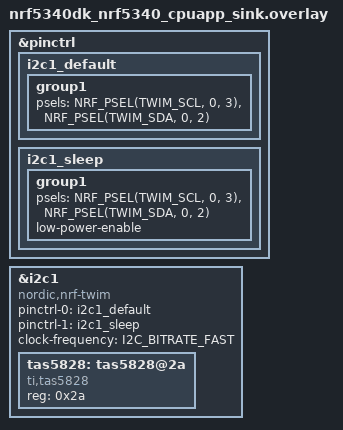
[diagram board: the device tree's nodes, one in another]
/*
 * boards/nrf5340dk_nrf5340_cpuapp_sink.overlay
 *
 * DTS overlay específico para builds de broadcast_sink (BT40NE).
 * Habilita I2C1 y declara el amplificador TAS5828.
 *
 * Pines I2C confirmados para TAS5828:
 *   SCL → P0.03
 *   SDA → P0.02
 *   I2C address TAS5828 → 0x2A  (ADDR pin = GND)
 *
 * Copyright (c) 2026
 * SPDX-License-Identifier: LicenseRef-Nordic-5-Clause
 */

&pinctrl {
	/* I2C1 pinctrl — TAS5828: SCL=P0.03, SDA=P0.02 */
	i2c1_default: i2c1_default {
		group1 {
			psels = <NRF_PSEL(TWIM_SCL, 0, 3)>,
				<NRF_PSEL(TWIM_SDA, 0, 2)>;
		};
	};

	i2c1_sleep: i2c1_sleep {
		group1 {
			psels = <NRF_PSEL(TWIM_SCL, 0, 3)>,
				<NRF_PSEL(TWIM_SDA, 0, 2)>;
			low-power-enable;
		};
	};
};

&i2c1 {
	compatible = "nordic,nrf-twim";
	status = "okay";
	pinctrl-0 = <&i2c1_default>;
	pinctrl-1 = <&i2c1_sleep>;
	pinctrl-names = "default", "sleep";
	clock-frequency = <I2C_BITRATE_FAST>;   /* 400 kHz */

	tas5828: tas5828@2a {
		compatible = "ti,tas5828";
		reg = <0x2a>;
		status = "okay";
	};
};
